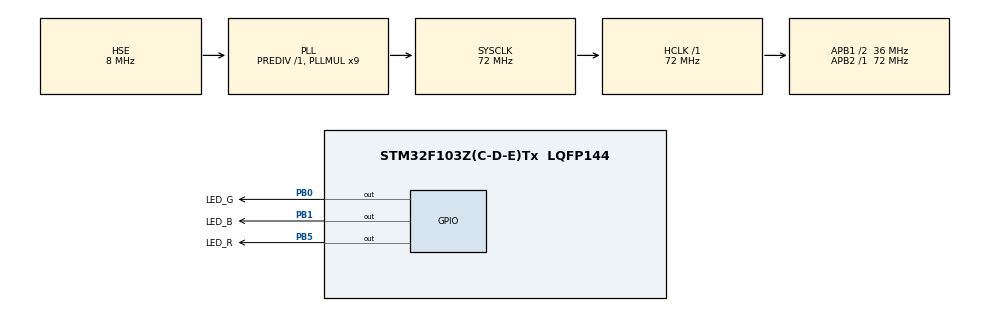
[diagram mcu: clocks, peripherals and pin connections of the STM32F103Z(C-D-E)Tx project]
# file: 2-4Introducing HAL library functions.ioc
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Mcu.Family=STM32F1
Mcu.Name=STM32F103Z(C-D-E)Tx
Mcu.Package=LQFP144
NVIC.PriorityGroup=NVIC_PRIORITYGROUP_4
OSC_IN.Mode=HSE-External-Oscillator
OSC_IN.Signal=RCC_OSC_IN
OSC_OUT.Mode=HSE-External-Oscillator
OSC_OUT.Signal=RCC_OSC_OUT
PA13.Mode=Serial_Wire
PA13.Signal=SYS_JTMS-SWDIO
PA14.Mode=Serial_Wire
PA14.Signal=SYS_JTCK-SWCLK
PB0.GPIO_Label=LED_G
PB0.PinState=GPIO_PIN_SET
PB0.Signal=GPIO_Output
PB1.GPIO_Label=LED_B
PB1.PinState=GPIO_PIN_SET
PB1.Signal=GPIO_Output
PB5.GPIO_Label=LED_R
PB5.PinState=GPIO_PIN_SET
PB5.Signal=GPIO_Output
PC14-OSC32_IN.Mode=LSE-External-Oscillator
PC14-OSC32_IN.Signal=RCC_OSC32_IN
PC15-OSC32_OUT.Mode=LSE-External-Oscillator
PC15-OSC32_OUT.Signal=RCC_OSC32_OUT
ProjectManager.HeapSize=0x200
ProjectManager.StackSize=0x400
ProjectManager.TargetToolchain=MDK-ARM V5
RCC.AHBFreq_Value=72000000
RCC.APB1CLKDivider=RCC_HCLK_DIV2
RCC.APB1Freq_Value=36000000
RCC.APB1TimFreq_Value=72000000
RCC.APB2Freq_Value=72000000
RCC.APB2TimFreq_Value=72000000
RCC.HCLKFreq_Value=72000000
RCC.PLLMUL=RCC_PLL_MUL9
RCC.PLLSourceVirtual=RCC_PLLSOURCE_HSE
RCC.SYSCLKFreq_VALUE=72000000
RCC.SYSCLKSource=RCC_SYSCLKSOURCE_PLLCLK
RCC.USBFreq_Value=72000000
board=custom

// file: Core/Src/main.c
/* USER CODE BEGIN Header */
/**
  ******************************************************************************
  * @file           : main.c
  * @brief          : Main program body
  ******************************************************************************
  * @attention
  *
  * Copyright (c) 2025 STMicroelectronics.
  * All rights reserved.
  *
  * This software is licensed under terms that can be found in the LICENSE file
  * in the root directory of this software component.
  * If no LICENSE file comes with this software, it is provided AS-IS.
  *
  ******************************************************************************
  */
/* USER CODE END Header */
#include "main.h"

void SystemClock_Config(void);
static void MX_GPIO_Init(void);

int main(void)
{

  /* MCU Configuration--------------------------------------------------------*/

  /* Reset of all peripherals, Initializes the Flash interface and the Systick. */
  HAL_Init();

  /* Configure the system clock */
  SystemClock_Config();

  /* Initialize all configured peripherals */
  MX_GPIO_Init();

  /* Infinite loop */
  while (1)
  {

    /* USER CODE BEGIN 3 */

    // // 使用WritePin函数控制LED灯的亮灭
    // HAL_GPIO_WritePin(LED_B_GPIO_Port, LED_B_Pin, GPIO_PIN_SET);   // 蓝灯关
    // HAL_GPIO_WritePin(LED_R_GPIO_Port, LED_R_Pin, GPIO_PIN_RESET); // 红灯开
    // HAL_Delay(500);
    // HAL_GPIO_WritePin(LED_R_GPIO_Port, LED_R_Pin, GPIO_PIN_SET);   // 红灯关
    // HAL_GPIO_WritePin(LED_G_GPIO_Port, LED_G_Pin, GPIO_PIN_RESET); // 绿灯开
    // HAL_Delay(500);
    // HAL_GPIO_WritePin(LED_G_GPIO_Port, LED_G_Pin, GPIO_PIN_SET);   // 绿灯关
    // HAL_GPIO_WritePin(LED_B_GPIO_Port, LED_B_Pin, GPIO_PIN_RESET); // 蓝灯开
    // HAL_Delay(500);

    // // 使用TogglePin函数控制LED灯的亮灭
    // HAL_GPIO_TogglePin(LED_B_GPIO_Port, LED_B_Pin); // 蓝灯状态取反
    // HAL_Delay(500);
    // HAL_GPIO_TogglePin(LED_R_GPIO_Port, LED_R_Pin); // 红灯状态取反
    // HAL_Delay(500);
    // HAL_GPIO_TogglePin(LED_G_GPIO_Port, LED_G_Pin); // 绿灯状态取反
    // HAL_Delay(500);

  }
  /* USER CODE END 3 */
}

void SystemClock_Config(void)
{
  RCC_OscInitTypeDef RCC_OscInitStruct = {0};
  RCC_ClkInitTypeDef RCC_ClkInitStruct = {0};

  /** Initializes the RCC Oscillators according to the specified parameters
  * in the RCC_OscInitTypeDef structure.
  */
  RCC_OscInitStruct.OscillatorType = RCC_OSCILLATORTYPE_HSE;
  RCC_OscInitStruct.HSEState = RCC_HSE_ON;
  RCC_OscInitStruct.HSEPredivValue = RCC_HSE_PREDIV_DIV1;
  RCC_OscInitStruct.HSIState = RCC_HSI_ON;
  RCC_OscInitStruct.PLL.PLLState = RCC_PLL_ON;
  RCC_OscInitStruct.PLL.PLLSource = RCC_PLLSOURCE_HSE;
  RCC_OscInitStruct.PLL.PLLMUL = RCC_PLL_MUL9;
  if (HAL_RCC_OscConfig(&RCC_OscInitStruct) != HAL_OK)
  {
    Error_Handler();
  }

  /** Initializes the CPU, AHB and APB buses clocks
  */
  RCC_ClkInitStruct.ClockType = RCC_CLOCKTYPE_HCLK|RCC_CLOCKTYPE_SYSCLK
                              |RCC_CLOCKTYPE_PCLK1|RCC_CLOCKTYPE_PCLK2;
  RCC_ClkInitStruct.SYSCLKSource = RCC_SYSCLKSOURCE_PLLCLK;
  RCC_ClkInitStruct.AHBCLKDivider = RCC_SYSCLK_DIV1;
  RCC_ClkInitStruct.APB1CLKDivider = RCC_HCLK_DIV2;
  RCC_ClkInitStruct.APB2CLKDivider = RCC_HCLK_DIV1;

  if (HAL_RCC_ClockConfig(&RCC_ClkInitStruct, FLASH_LATENCY_2) != HAL_OK)
  {
    Error_Handler();
  }
}

static void MX_GPIO_Init(void)
{
  GPIO_InitTypeDef GPIO_InitStruct = {0};

  /* GPIO Ports Clock Enable */
  __HAL_RCC_GPIOC_CLK_ENABLE();
  __HAL_RCC_GPIOB_CLK_ENABLE();
  __HAL_RCC_GPIOA_CLK_ENABLE();

  /*Configure GPIO pin Output Level */
  HAL_GPIO_WritePin(GPIOB, LED_G_Pin|LED_B_Pin|LED_R_Pin, GPIO_PIN_SET);

  /*Configure GPIO pins : LED_G_Pin LED_B_Pin LED_R_Pin */
  GPIO_InitStruct.Pin = LED_G_Pin|LED_B_Pin|LED_R_Pin;
  GPIO_InitStruct.Mode = GPIO_MODE_OUTPUT_PP;
  GPIO_InitStruct.Pull = GPIO_NOPULL;
  GPIO_InitStruct.Speed = GPIO_SPEED_FREQ_LOW;
  HAL_GPIO_Init(GPIOB, &GPIO_InitStruct);

}

void Error_Handler(void)
{
  __disable_irq();
  while (1)
  {
  }
}
